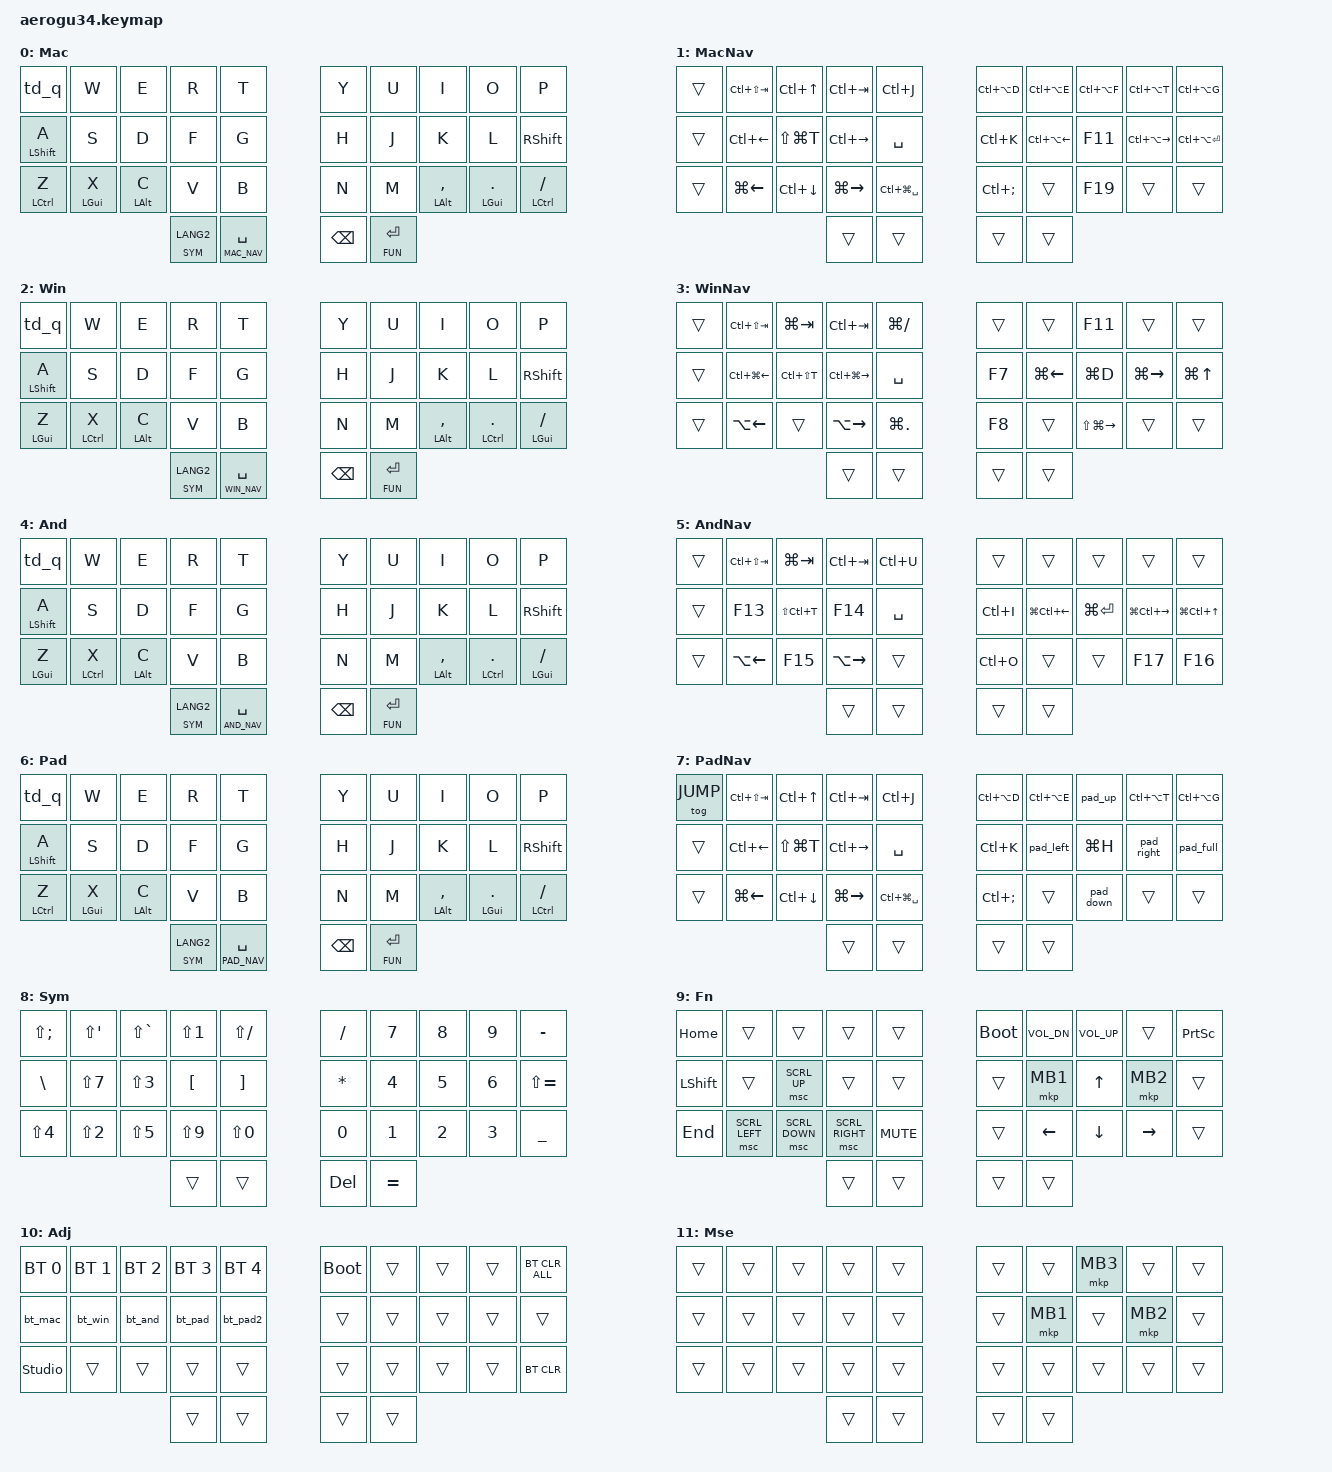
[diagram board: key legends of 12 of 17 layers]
// =====================================================================
// Aerogu34 keymap — Hiro版 v1.4（LiNEA40からの移植）
// 設計メモ:
//   - レイヤー番号は必ず下のdefineで参照する（番号直書き禁止・LiNEA40の轍を踏まない）
//   - ベース3段30キーはLiNEA40と同一。下段11キー→親指4キーへ再編
//   - A長押しShift＋下段ホールドMod（誤爆対策チューニング済み）
//   - トラボ: 玉を動かすとMOUSEレイヤー(11)が自動有効(AML)、
//     SYMレイヤー(8)ホールド中はスクロール（右overlay側の2行と整合済み）
//   - v1.9 Jumpモード: iPadのJump Desktopから母艦Macを操作するとき用の上乗せ層(12〜16)。
//     PadNavのQ（Space長押し＋Q）で入切。入っている間は右手のLEDが緑。
//     iPadが横取りするキーを「Ctrl+Option+英字」の合図に置き換え、母艦のBetterTouchToolが
//     受けて動作する（Macのショートカット・Mac層・既存の層0〜11は変えない）。
//     合図: X=Mission Control / A=英数 / H=かな / S=スクリーンショット / L=Alfred / Y=Tab（v1.9.2）
//     （Mは使わない: 母艦のAqua Voiceの「会議の録音」= Option+M と重なるため）
//   - v1.9.3 iPadのウインドウ操作: PadNavの I/J/L/,/; = 上/左/右/下/フルスクリーン（地球儀を使うiPadの
//     ショートカット）。Jumpモード中は、同じ位置を母艦用のキーのまま残す（Jump Nav層）。
//   - v1.9.4 Jumpモードの手直し: Alfredの合図は、Cmdを先に離してから一定の長さで送る（&jump_alfred）
//     音声入力: Jumpモードの ,+. = iPadの言語を切り替えてからiPad純正の音声入力（&jump_dict）／
//     .+/ = iPadのキーボードの言語の切り替え（Ctrl+Space）。前提: iPadのJump Desktopの設定
//     「Switch Languages On」が This iPad（Jumpの中のCtrl+SpaceがiPadの言語を切り替える）
// =====================================================================

#define ZMK_POINTING_DEFAULT_SCRL_VAL 150

#include <dt-bindings/zmk/mouse.h>
#include <behaviors.dtsi>
#include <dt-bindings/zmk/bt.h>
#include <dt-bindings/zmk/keys.h>
#include <dt-bindings/zmk/pointing.h>

// ---- レイヤー定義（唯一の正） ----
#define MAC      0
#define MAC_NAV  1
#define WIN      2
#define WIN_NAV  3
#define AND      4
#define AND_NAV  5
#define PAD      6
#define PAD_NAV  7
#define SYM      8   // 記号＋テンキー（右overlayのスクロール指定と連動）
#define FUN      9
#define ADJ      10  // SYM+FUN同時押しで出現
#define MSE      11  // 自動マウスレイヤー（右overlayのAML指定と連動）
// ---- Jumpモード（v1.9）。12以降は「透過が基本」の上乗せ層 ----
#define JUMP     12  // PadNavのQで入切。右overlayのjscroll（スクロール1/10）がBIT(12)で連動
#define JUMP_NAV 13  // 以下4つは条件付きレイヤー（JUMPと対の層が両方有効な間だけ自動で重なる）。
#define JUMP_SYM 14  //   コンボは「最上位の有効層」で判定されるため、Nav/Sym/Fn/Mseの間は
#define JUMP_FUN 15  //   これらが最上位になり、Jump用コンボが誤発動しない
#define JUMP_MSE 16  //   （例: Sym層で"45"や"23"を速く打っても、かな・音声入力に化けない）

// ---- キー位置（hold-trigger用） ----
//  0  1  2  3  4   |   5  6  7  8  9
// 10 11 12 13 14   |  15 16 17 18 19
// 20 21 22 23 24   |  25 26 27 28 29
//        30 31     |  32 33
#define KEYS_L 0 1 2 3 4 10 11 12 13 14 20 21 22 23 24
#define KEYS_R 5 6 7 8 9 15 16 17 18 19 25 26 27 28 29
#define THUMBS_L 30 31
#define THUMBS_R 32 33

// マウススクロール（Funcレイヤーのスクロールキー用・LiNEA40の設定を踏襲）
&msc {
    delay-ms = <3>;
    trigger-period-ms = <3>;
    time-to-max-speed-ms = <100>;
    acceleration-exponent = <0>;
};

// レイヤータップ: タップ→即ホールドでキーリピート（Space連打対応）
&lt { quick-tap-ms = <300>; };

/ {
    behaviors {
        // 左手用ホールドMod（A長押しShift・Z/X/C）
        // 反対手（右手＋右親指）のキーだけがホールドを起動する
        hml: homerow_mod_left {
            compatible = "zmk,behavior-hold-tap";
            #binding-cells = <2>;
            flavor = "balanced";
            tapping-term-ms = <280>;
            quick-tap-ms = <175>;
            require-prior-idle-ms = <150>;
            hold-trigger-key-positions = <KEYS_R THUMBS_R>;
            hold-trigger-on-release;
            bindings = <&kp>, <&kp>;
        };

        // Z専用ホールドMod（tap-preferred）
        // Google日本語入力の z+h/j/k/l（←↓↑→入力）を守るための特別扱い。
        // 巻き込み（ロール）では絶対にCtrl化せず、280ms以上「押し続けた時だけ」Ctrlになる。
        // ※zh等が誤ってCtrl+Hになる場合はtapping-termを伸ばす
        hml_tp: homerow_mod_left_tap_pref {
            compatible = "zmk,behavior-hold-tap";
            #binding-cells = <2>;
            flavor = "tap-preferred";
            tapping-term-ms = <280>;
            quick-tap-ms = <175>;
            require-prior-idle-ms = <150>;
            hold-trigger-key-positions = <KEYS_R THUMBS_R>;
            bindings = <&kp>, <&kp>;
        };

        // Q = 1回タップでQ、素早く2回タップでEsc（v1.2）
        // 他のキーを打った瞬間に確定するので、通常入力の遅延は実質なし
        td_q: tap_dance_q_esc {
            compatible = "zmk,behavior-tap-dance";
            #binding-cells = <0>;
            tapping-term-ms = <200>;
            bindings = <&kp Q>, <&kp ESC>;
        };

        // 右手用ホールドMod（,/./スラッシュ）
        hmr: homerow_mod_right {
            compatible = "zmk,behavior-hold-tap";
            #binding-cells = <2>;
            flavor = "balanced";
            tapping-term-ms = <280>;
            quick-tap-ms = <175>;
            require-prior-idle-ms = <150>;
            hold-trigger-key-positions = <KEYS_L THUMBS_L>;
            hold-trigger-on-release;
            bindings = <&kp>, <&kp>;
        };

        // Jumpモード用のSpace（v1.9）
        // Cmd(GUI)が押されている間だけ、Alfred用の合図（Ctrl+Option+L）を送る。
        // iPadが Cmd+Space を自分の検索として横取りするため。合図はCmdを外して送られる。
        // Cmdなしのときは通常どおり Space（長押しでPadNav）。
        // v1.9.4: 合図の出し方を &jump_alfred（マクロ）に変えた。Cmdを先に離してから、合図を一定の長さで送る
        jump_space: jump_space {
            compatible = "zmk,behavior-mod-morph";
            #binding-cells = <0>;
            bindings = <&lt PAD_NAV SPACE>, <&jump_alfred>;
            mods = <(MOD_LGUI|MOD_RGUI)>;
        };

        // Jumpモード用のTab（v1.9.2）
        // iPadにつないだキーボードの素のTabは、Jump Desktop経由では母艦で効かなかった
        // （2026-11-16 の実機。原因は未確定）。Jumpモード中のS+Dは、Tabの合図（Ctrl+Option+Y）を送り、
        // 母艦のBetterTouchToolがTabに変換する。Shiftを押していれば Ctrl+Option+Shift+Y（＝Shift+Tab用）。
        // Option・Ctrl・Cmd のどれかを押している間は、今までどおりTabを送る（押している修飾キーは残す）
        // ＝Option+Tab（Jump Desktopが母艦のアプリ切替に変換する）・Ctrl+Tab・Cmd+Tab（iPadのアプリ切替）はそのまま。
        jump_tab: jump_tab {
            compatible = "zmk,behavior-mod-morph";
            #binding-cells = <0>;
            bindings = <&kp LC(LA(Y))>, <&kp TAB>;
            mods = <(MOD_LALT|MOD_RALT|MOD_LCTL|MOD_RCTL|MOD_LGUI|MOD_RGUI)>;
            keep-mods = <(MOD_LALT|MOD_RALT|MOD_LCTL|MOD_RCTL|MOD_LGUI|MOD_RGUI)>;
        };
    };

    combos {
        compatible = "zmk,combos";

        // S+D = Tab（LiNEA40から継続）
        tab {
            bindings = <&kp TAB>;
            key-positions = <11 12>;
            layers = <MAC WIN AND PAD>;
        };

        // S+D = Tab（Jumpモード用・v1.9.2）: Tabの合図（Ctrl+Option+Y）。Option・Ctrl・Cmd併用時は素のTab
        tab_jump {
            bindings = <&jump_tab>;
            key-positions = <11 12>;
            layers = <JUMP>;
        };

        // J+K = かな（旧・左親指かなキーの移設。ローマ字にjkの並びは無く安全）
        kana {
            bindings = <&kp LANG1>;
            key-positions = <16 17>;
            layers = <MAC WIN AND PAD>;
        };

        // J+K = かな（Jumpモード用・v1.9）
        // 母艦のBetterTouchToolが「かな」キーに変換する合図（Ctrl+Option+H）を送る
        kana_jump {
            bindings = <&kp LC(LA(H))>;
            key-positions = <16 17>;
            layers = <JUMP>;
        };

        // カンマ+ピリオド = Alt+Space（Aqua Voiceハンズフリー・存続。v1.9: Mac/Win/Andのみ）
        aqua_handsfree {
            bindings = <&kp RA(SPACE)>;
            key-positions = <27 28>;
            layers = <MAC WIN AND>;
        };

        // カンマ+ピリオド = 地球儀+D（iPad純正の音声入力・v1.9）: Pad層
        // （v1.9.4: Jumpモードは下の dictation_jump に分けた）
        dictation_ipad {
            bindings = <&globe_d>;
            key-positions = <27 28>;
            layers = <PAD>;
        };

        // カンマ+ピリオド = 音声入力（Jumpモード用・v1.9.4）
        // iPadのキーボードの言語を切り替えてから、iPad純正の音声入力を始める（&jump_dict）。
        // Jump Desktopの中では、iPadが英語のときは母艦で変換でき、日本語のときは音声入力が
        // 日本語を聞き取る（本人の実機 2026-11-26）。ふだんは英語なので、押すと日本語になって始まる
        dictation_jump {
            bindings = <&jump_dict>;
            key-positions = <27 28>;
            layers = <JUMP>;
        };

        // ピリオド+スラッシュ = iPadのキーボードの言語の切り替え（Jumpモード用・v1.9.4）: Ctrl+Space を1回（&ipad_lang）
        // 音声入力の後に英語へ戻すとき・文字を打って左下にiPadの変換候補（黒い帯）が出たときに押す
        ipad_lang_jump {
            bindings = <&ipad_lang>;
            key-positions = <28 29>;
            layers = <JUMP>;
        };
    };

    macros {
        bt_mac: bt_mac {
            compatible = "zmk,behavior-macro";
            #binding-cells = <0>;
            bindings = <&bt BT_SEL 0>, <&macro_wait_time 200>, <&to MAC>;
            label = "BT_MAC";
        };

        bt_win: bt_win {
            compatible = "zmk,behavior-macro";
            #binding-cells = <0>;
            bindings = <&bt BT_SEL 1>, <&macro_wait_time 200>, <&to WIN>;
            label = "BT_WIN";
        };

        bt_and: bt_and {
            compatible = "zmk,behavior-macro";
            #binding-cells = <0>;
            bindings = <&bt BT_SEL 2>, <&macro_wait_time 200>, <&to AND>;
            label = "BT_AND";
        };

        bt_pad: bt_pad {
            compatible = "zmk,behavior-macro";
            #binding-cells = <0>;
            bindings = <&bt BT_SEL 3>, <&macro_wait_time 200>, <&to PAD>;
            label = "BT_PAD";
        };

        // v1.9: 接続先4番を Win2（GPD MicroPC 2）から iPad mini 用（Pad層）に振り替え
        bt_pad2: bt_pad2 {
            compatible = "zmk,behavior-macro";
            #binding-cells = <0>;
            bindings = <&bt BT_SEL 4>, <&macro_wait_time 200>, <&to PAD>;
            label = "BT_PAD2";
        };

        // iPad純正の音声入力（v1.9）: 地球儀を押したまま D
        globe_d: globe_d {
            compatible = "zmk,behavior-macro";
            #binding-cells = <0>;
            bindings = <&macro_press &kp GLOBE>, <&macro_tap &kp D>, <&macro_release &kp GLOBE>;
            label = "GLOBE_D";
        };

        // iPadのウインドウ操作（v1.9.3）: iPadのメニュー「ウインドウ」に出ているショートカットを送る。
        // 地球儀を押したまま（左右上下はCtrlも押したまま）キーを1回押す。作りは globe_d と同じ
        // フルスクリーンにする = 地球儀+F
        pad_full: pad_full {
            compatible = "zmk,behavior-macro";
            #binding-cells = <0>;
            bindings = <&macro_press &kp GLOBE>, <&macro_tap &kp F>, <&macro_release &kp GLOBE>;
            label = "PAD_FULL";
        };
        // 左（2分割）= Ctrl+地球儀+←
        pad_left: pad_left {
            compatible = "zmk,behavior-macro";
            #binding-cells = <0>;
            bindings = <&macro_press &kp LCTRL &kp GLOBE>, <&macro_tap &kp LEFT>, <&macro_release &kp GLOBE &kp LCTRL>;
            label = "PAD_LEFT";
        };
        // 右（2分割）= Ctrl+地球儀+→
        pad_right: pad_right {
            compatible = "zmk,behavior-macro";
            #binding-cells = <0>;
            bindings = <&macro_press &kp LCTRL &kp GLOBE>, <&macro_tap &kp RIGHT>, <&macro_release &kp GLOBE &kp LCTRL>;
            label = "PAD_RIGHT";
        };
        // 上（2分割）= Ctrl+地球儀+↑
        pad_up: pad_up {
            compatible = "zmk,behavior-macro";
            #binding-cells = <0>;
            bindings = <&macro_press &kp LCTRL &kp GLOBE>, <&macro_tap &kp UP>, <&macro_release &kp GLOBE &kp LCTRL>;
            label = "PAD_UP";
        };
        // 下（2分割）= Ctrl+地球儀+↓
        pad_down: pad_down {
            compatible = "zmk,behavior-macro";
            #binding-cells = <0>;
            bindings = <&macro_press &kp LCTRL &kp GLOBE>, <&macro_tap &kp DOWN>, <&macro_release &kp GLOBE &kp LCTRL>;
            label = "PAD_DOWN";
        };

        // JumpモードのAlfred用（v1.9.4）: Cmdを離す → 0.05秒待つ → 合図（Ctrl+Option+L）を0.1秒出す。
        // v1.9.3までは「Cmdを隠すのと合図を出すのが同じ瞬間・合図の長さはSpaceを押している間」で、
        // iPad→Jump Desktop→母艦の経路で、できたりできなかったりした（本人の実機 2026-11-25）。
        // このキーボードのCmdはLGUIだけ（X と . の長押し）。Cmdのキーを押したままでも、ここでCmdは
        // 離した扱いになる（続けてもう一度Alfredを出すには、Cmdを押し直す）
        jump_alfred: jump_alfred {
            compatible = "zmk,behavior-macro";
            #binding-cells = <0>;
            wait-ms = <50>;
            tap-ms = <100>;
            bindings = <&macro_release &kp LGUI>, <&macro_tap &kp LC(LA(L))>;
            label = "JUMP_ALFRED";
        };

        // Jumpモードの音声入力（v1.9.4）: Ctrl+Space を0.06秒（iPadの言語を切り替える）→ 0.6秒待つ →
        // 地球儀を押したまま D（iPad純正の音声入力。ここの長さは globe_d と同じ）。
        // iPadが英語の状態で押す前提（日本語になって始まる）。
        // iPadが日本語の状態で押すと、英語になってから始まってしまう（そのときは .+/ で言語を直す）
        jump_dict: jump_dict {
            compatible = "zmk,behavior-macro";
            #binding-cells = <0>;
            bindings = <&macro_tap_time 60>, <&macro_wait_time 600>, <&macro_tap &kp LC(SPACE)>,
                       <&macro_tap_time 30>, <&macro_wait_time 15>, <&macro_press &kp GLOBE>, <&macro_tap &kp D>, <&macro_release &kp GLOBE>;
            label = "JUMP_DICT";
        };

        // iPadのキーボードの言語の切り替え（v1.9.4）: Ctrl+Space を0.06秒で1回だけ送る。
        // キーを押し続けても1回だけ（押している間じゅうCtrl+Spaceを出し続けると、iPadが言語の
        // 一覧を出したり、何度も切り替えたりするおそれがあるため。Codexの9回目の指摘）
        ipad_lang: ipad_lang {
            compatible = "zmk,behavior-macro";
            #binding-cells = <0>;
            tap-ms = <60>;
            bindings = <&macro_tap &kp LC(SPACE)>;
            label = "IPAD_LANG";
        };
    };

    keymap {
        compatible = "zmk,keymap";

        // ============ 0: Mac ============
        Mac_Base {
            display-name = "Mac";
            bindings = <
&td_q           &kp W         &kp E         &kp R   &kp T          &kp Y   &kp U   &kp I            &kp O           &kp P
&hml LSHFT A    &kp S         &kp D         &kp F   &kp G          &kp H   &kp J   &kp K            &kp L           &kp RSHIFT
&hml_tp LCTRL Z &hml LGUI X   &hml LALT C   &kp V   &kp B          &kp N   &kp M   &hmr LALT COMMA  &hmr LGUI DOT   &hmr LCTRL SLASH
                              &lt SYM LANG2  &lt MAC_NAV SPACE     &kp BACKSPACE   &lt FUN ENTER
            >;
        };

        // ============ 1: Mac Nav（旧Mac_Win・3段は完全移植） ============
        Mac_Nav {
            display-name = "MacNav";
            bindings = <
&trans  &kp LC(LS(TAB))  &kp LC(UP)     &kp LC(TAB)    &kp LC(J)              &kp LC(LA(D))  &kp LC(LA(E))     &kp LC(LA(F))  &kp LC(LA(T))      &kp LC(LA(G))
&trans  &kp LC(LEFT)     &kp LS(LG(T))  &kp LC(RIGHT)  &kp SPACE              &kp LC(K)      &kp LC(LA(LEFT))  &kp F11        &kp LC(LA(RIGHT))  &kp LC(LA(ENTER))
&trans  &kp LG(LEFT)     &kp LC(DOWN)   &kp LG(RIGHT)  &kp LC(LG(SPACE))      &kp LC(SEMI)   &trans            &kp F19        &trans             &trans
                         &trans         &trans                                &trans         &trans
            >;
        };

        // ============ 2: Windows（v1.4: GUI⇔Ctrl入替＝主修飾CtrlをMacのCmdと同位置X/.に） ============
        Win_Base {
            display-name = "Win";
            bindings = <
&td_q           &kp W         &kp E         &kp R   &kp T          &kp Y   &kp U   &kp I            &kp O           &kp P
&hml LSHFT A    &kp S         &kp D         &kp F   &kp G          &kp H   &kp J   &kp K            &kp L           &kp RSHIFT
&hml_tp LGUI Z  &hml LCTRL X  &hml LALT C   &kp V   &kp B          &kp N   &kp M   &hmr LALT COMMA  &hmr LCTRL DOT  &hmr LGUI SLASH
                              &lt SYM LANG2  &lt WIN_NAV SPACE     &kp BACKSPACE   &lt FUN ENTER
            >;
        };

        // ============ 3: Win Nav（旧Win_Win・3段は完全移植） ============
        Win_Nav {
            display-name = "WinNav";
            bindings = <
&trans  &kp LC(LS(TAB))   &kp LG(TAB)    &kp LC(TAB)        &kp LG(SLASH)       &trans  &trans        &kp F11            &trans         &trans
&trans  &kp LC(LG(LEFT))  &kp LC(LS(T))  &kp LC(LG(RIGHT))  &kp SPACE           &kp F7  &kp LG(LEFT)  &kp LG(D)          &kp LG(RIGHT)  &kp LG(UP)
&trans  &kp LA(LEFT)      &trans         &kp LA(RIGHT)      &kp LG(PERIOD)      &kp F8  &trans        &kp LS(LG(RIGHT))  &trans         &trans
                          &trans         &trans                                 &trans  &trans
            >;
        };

        // ============ 4: Android（v1.4: Winと同じくGUI⇔Ctrl入替） ============
        And_Base {
            display-name = "And";
            bindings = <
&td_q           &kp W         &kp E         &kp R   &kp T          &kp Y   &kp U   &kp I            &kp O           &kp P
&hml LSHFT A    &kp S         &kp D         &kp F   &kp G          &kp H   &kp J   &kp K            &kp L           &kp RSHIFT
&hml_tp LGUI Z  &hml LCTRL X  &hml LALT C   &kp V   &kp B          &kp N   &kp M   &hmr LALT COMMA  &hmr LCTRL DOT  &hmr LGUI SLASH
                              &lt SYM LANG2  &lt AND_NAV SPACE     &kp BACKSPACE   &lt FUN ENTER
            >;
        };

        // ============ 5: And Nav（旧And_Win・3段は完全移植） ============
        And_Nav {
            display-name = "AndNav";
            bindings = <
&trans  &kp LC(LS(TAB))  &kp LG(TAB)    &kp LC(TAB)    &kp LC(U)      &trans     &trans            &trans         &trans             &trans
&trans  &kp F13          &kp LS(LC(T))  &kp F14        &kp SPACE      &kp LC(I)  &kp LG(LC(LEFT))  &kp LG(ENTER)  &kp LG(LC(RIGHT))  &kp LG(LC(UP))
&trans  &kp LA(LEFT)     &kp F15        &kp LA(RIGHT)  &trans         &kp LC(O)  &trans            &trans         &kp F17            &kp F16
                         &trans         &trans                        &trans     &trans
            >;
        };

        // ============ 6: iPad ============
        Pad_Base {
            display-name = "Pad";
            bindings = <
&td_q           &kp W         &kp E         &kp R   &kp T          &kp Y   &kp U   &kp I            &kp O           &kp P
&hml LSHFT A    &kp S         &kp D         &kp F   &kp G          &kp H   &kp J   &kp K            &kp L           &kp RSHIFT
&hml_tp LCTRL Z &hml LGUI X   &hml LALT C   &kp V   &kp B          &kp N   &kp M   &hmr LALT COMMA  &hmr LGUI DOT   &hmr LCTRL SLASH
                              &lt SYM LANG2  &lt PAD_NAV SPACE     &kp BACKSPACE   &lt FUN ENTER
            >;
        };

        // ============ 7: Pad Nav（旧Pad_Win・3段は完全移植） ============
        // v1.9: 左上（Qの位置）= Jumpモードの入切
        // v1.9.3: 右手の I/J/L/,/; = iPadのウインドウ操作（上・左・右・下・フルスクリーン）。
        //         Macのナビ層の「左半分・右半分・最大化」と同じ位置にそろえた。
        //         以前ここにあった母艦用のキーは、Jump Nav層（13）に移した
        Pad_Nav {
            display-name = "PadNav";
            bindings = <
&tog JUMP  &kp LC(LS(TAB))  &kp LC(UP)     &kp LC(TAB)    &kp LC(J)              &kp LC(LA(D))  &kp LC(LA(E))     &pad_up        &kp LC(LA(T))      &kp LC(LA(G))
&trans  &kp LC(LEFT)     &kp LS(LG(T))  &kp LC(RIGHT)  &kp SPACE              &kp LC(K)      &pad_left         &kp LG(H)      &pad_right         &pad_full
&trans  &kp LG(LEFT)     &kp LC(DOWN)   &kp LG(RIGHT)  &kp LC(LG(SPACE))      &kp LC(SEMI)   &trans            &pad_down      &trans             &trans
                         &trans         &trans                                &trans         &trans
            >;
        };

        // ============ 8: 記号＋テンキー（旧SymNum・3段は完全移植） ============
        // ホールド中はトラボがスクロールになる（右overlay側で指定）
        SymNum {
            display-name = "Sym";
            bindings = <
&kp LS(SEMI)  &kp LS(APOS)  &kp LS(GRAVE)  &kp LS(N1)  &kp LS(FSLH)      &kp SLASH  &kp N7  &kp N8  &kp N9  &kp MINUS
&kp BSLH      &kp LS(N7)    &kp LS(N3)     &kp LBKT    &kp RBKT          &kp ASTRK  &kp N4  &kp N5  &kp N6  &kp LS(EQUAL)
&kp LS(N4)    &kp LS(N2)    &kp LS(N5)     &kp LS(N9)  &kp LS(N0)        &kp N0     &kp N1  &kp N2  &kp N3  &kp UNDER
                            &trans         &trans                        &kp DEL    &kp EQUAL
            >;
        };

        // ============ 9: Func（3段は移植＋音量2キー追加・ENDを左下へ） ============
        Func {
            display-name = "Fn";
            bindings = <
&kp HOME    &trans           &trans           &trans            &trans            &bootloader  &kp C_VOL_DN  &kp C_VOL_UP  &trans     &kp PRINTSCREEN
&kp LSHIFT  &trans           &msc SCRL_UP     &trans            &trans            &trans       &mkp MB1      &kp UP        &mkp MB2   &trans
&kp END     &msc SCRL_LEFT   &msc SCRL_DOWN   &msc SCRL_RIGHT   &kp K_MUTE        &trans       &kp LEFT      &kp DOWN      &kp RIGHT  &trans
                             &trans           &trans                              &trans       &trans
            >;
        };

        // ============ 10: Adjust（SYM+FUN同時押し） ============
        Adjust {
            display-name = "Adj";
            bindings = <
&bt BT_SEL 0    &bt BT_SEL 1  &bt BT_SEL 2  &bt BT_SEL 3  &bt BT_SEL 4      &bootloader  &trans  &trans  &trans  &bt BT_CLR_ALL
&bt_mac         &bt_win       &bt_and       &bt_pad       &bt_pad2          &trans       &trans  &trans  &trans  &trans
&studio_unlock  &trans        &trans        &trans        &trans            &trans       &trans  &trans  &trans  &bt BT_CLR
                              &trans        &trans                          &trans       &trans
            >;
        };

        // ============ 11: Mouse（トラボを動かすと自動で有効・AML） ============
        // 最小構成（v1.4）: I=中クリック・J=左クリック・L=右クリックのみ。他は全て透過
        Mouse {
            display-name = "Mse";
            bindings = <
&trans     &trans     &trans    &trans    &trans      &trans    &trans    &mkp MB3  &trans    &trans
&trans     &trans     &trans    &trans    &trans      &trans    &mkp MB1  &trans    &mkp MB2  &trans
&trans     &trans     &trans    &trans    &trans      &trans    &trans    &trans    &trans    &trans
                      &trans    &trans                &trans    &trans
            >;
        };

        // ============ 12: Jump（iPadのJump Desktop用の上乗せ層・v1.9） ============
        // PadNavのQで入切。置き換えるのは親指の2キーだけ:
        //   左親指: タップ=英数の合図（Ctrl+Option+A）・長押しは今までどおりSym
        //   Space : Cmdを押している間だけAlfredの合図（&jump_space）。それ以外は通常のSpace／PadNav
        Jump {
            display-name = "Jump";
            bindings = <
&trans  &trans  &trans  &trans  &trans      &trans  &trans  &trans  &trans  &trans
&trans  &trans  &trans  &trans  &trans      &trans  &trans  &trans  &trans  &trans
&trans  &trans  &trans  &trans  &trans      &trans  &trans  &trans  &trans  &trans
                &lt SYM LC(LA(A))  &jump_space      &trans  &trans
            >;
        };

        // ============ 13: Jump Nav（JUMP＋PAD_NAVで自動） ============
        // E = Mission Controlの合図（Ctrl+Option+X）。iPadが Ctrl+↑ を横取りするため
        // v1.9.3: 右手の I/J/L/,/; = 母艦用のキー（Ctrl+Option+F/←/→/Enter・F19）。
        //         v1.9.2まではPad Navにあったもの。Pad Nav側がiPadのウインドウ操作になったので、
        //         ここに同じキーを置いて、Jumpモード中の動きを変えないようにした
        Jump_Nav {
            display-name = "JumpNav";
            bindings = <
&trans  &trans  &kp LC(LA(X))  &trans  &trans      &trans  &trans            &kp LC(LA(F))  &trans             &trans
&trans  &trans  &trans         &trans  &trans      &trans  &kp LC(LA(LEFT))  &trans         &kp LC(LA(RIGHT))  &kp LC(LA(ENTER))
&trans  &trans  &trans         &trans  &trans      &trans  &trans            &kp F19        &trans             &trans
                &trans  &trans      &trans  &trans
            >;
        };

        // ============ 14: Jump Sym（JUMP＋SYMで自動） ============
        // Sym中の最上位層をここにして、Jump用コンボを止めるための層
        // v1.9.3: 右手の I/J/L/;/, に、Sym層（8）と同じキーを置いた（8・4・6・+・2）。
        //         Jump Nav層（13）に母艦用のキーを置いたので、ナビとSymを同時に押したときに
        //         そちらが勝たないようにするため。Sym層のこの5か所を変えるときは、ここも同じにする
        Jump_Sym {
            display-name = "JumpSym";
            bindings = <
&trans  &trans  &trans  &trans  &trans      &trans  &trans   &kp N8  &trans   &trans
&trans  &trans  &trans  &trans  &trans      &trans  &kp N4   &trans  &kp N6   &kp LS(EQUAL)
&trans  &trans  &trans  &trans  &trans      &trans  &trans   &kp N2  &trans   &trans
                &trans  &trans      &trans  &trans
            >;
        };

        // ============ 15: Jump Fn（JUMP＋FUNで自動） ============
        // P = スクリーンショット（範囲）の合図（Ctrl+Option+S）。PRINTSCREENがJump経由で届かないため
        // ※Jumpモード中は Adjust＋P（BT CLR ALL）よりこちらが勝つ
        // v1.9.3: 右手の I/J/L/, に、Fn層（9）と同じキーを置いた（音量＋・左クリック・右クリック・↓）。
        //         理由はJump Symと同じ（ナビとFnを同時に押したときに、Jump Nav層が勝たないようにする）。
        //         Fn層のこの4か所を変えるときは、ここも同じにする
        Jump_Fn {
            display-name = "JumpFn";
            bindings = <
&trans  &trans  &trans  &trans  &trans      &trans  &trans    &kp C_VOL_UP  &trans    &kp LC(LA(S))
&trans  &trans  &trans  &trans  &trans      &trans  &mkp MB1  &trans        &mkp MB2  &trans
&trans  &trans  &trans  &trans  &trans      &trans  &trans    &kp DOWN      &trans    &trans
                &trans  &trans      &trans  &trans
            >;
        };

        // ============ 16: Jump Mouse（JUMP＋MSEで自動） ============
        // 玉を動かしている間の最上位層をここにして、Jump用コンボを止めるための層
        // v1.9.3: 右手の I/J/L に、Mouse層（11）と同じクリックを置いた（中・左・右）。
        //         理由はJump Symと同じ（ナビを押したまま玉を動かしたときに、Jump Nav層が勝たないようにする）。
        //         Mouse層のクリックの位置を変えるときは、ここも同じにする
        Jump_Mse {
            display-name = "JumpMse";
            bindings = <
&trans  &trans  &trans  &trans  &trans      &trans  &trans    &mkp MB3  &trans    &trans
&trans  &trans  &trans  &trans  &trans      &trans  &mkp MB1  &trans    &mkp MB2  &trans
&trans  &trans  &trans  &trans  &trans      &trans  &trans  &trans  &trans  &trans
                &trans  &trans      &trans  &trans
            >;
        };
    };

    conditional_layers {
        compatible = "zmk,conditional-layers";

        adjust {
            if-layers = <SYM FUN>;
            then-layer = <ADJ>;
        };

        // v1.9: Jumpモード中、対になる層が有効な間だけ重なる層
        jump_nav {
            if-layers = <PAD_NAV JUMP>;
            then-layer = <JUMP_NAV>;
        };

        jump_sym {
            if-layers = <SYM JUMP>;
            then-layer = <JUMP_SYM>;
        };

        jump_fun {
            if-layers = <FUN JUMP>;
            then-layer = <JUMP_FUN>;
        };

        jump_mse {
            if-layers = <MSE JUMP>;
            then-layer = <JUMP_MSE>;
        };
    };
};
